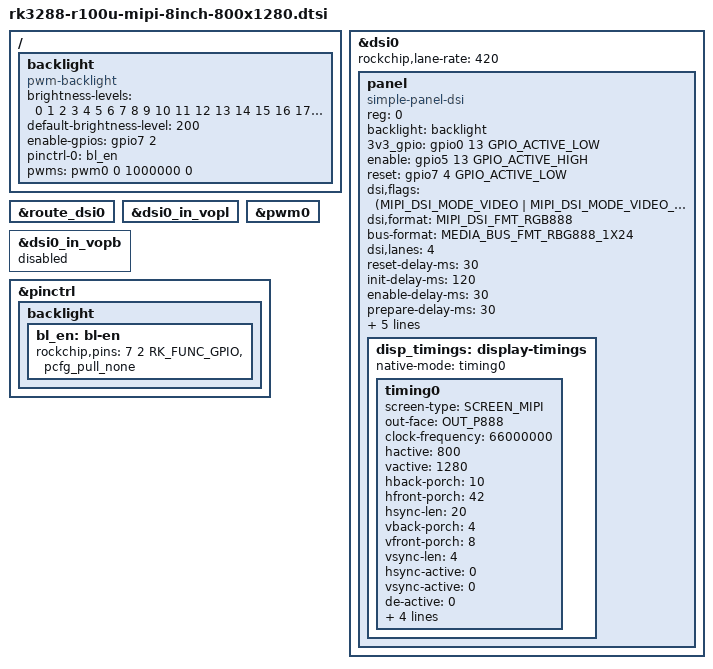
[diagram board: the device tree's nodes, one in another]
// #include <dt-bindings/pwm/pwm.h>
/ {
    /* about backlight */

    backlight: backlight {
    compatible = "pwm-backlight";
    brightness-levels = 
        <
          0   1   2   3   4   5   6   7
          8   9  10  11  12  13  14  15
         16  17  18  19  20  21  22  23
         24  25  26  27  28  29  30  31
         32  33  34  35  36  37  38  39
         40  41  42  43  44  45  46  47
         48  49  50  51  52  53  54  55
         56  57  58  59  60  61  62  63
         64  65  66  67  68  69  70  71
         72  73  74  75  76  77  78  79
         80  81  82  83  84  85  86  87
         88  89  90  91  92  93  94  95
         96  97  98  99 100 101 102 103
        104 105 106 107 108 109 110 111
        112 113 114 115 116 117 118 119
        120 121 122 123 124 125 126 127
        128 129 130 131 132 133 134 135
        136 137 138 139 140 141 142 143
        144 145 146 147 148 149 150 151
        152 153 154 155 156 157 158 159
        160 161 162 163 164 165 166 167
        168 169 170 171 172 173 174 175
        176 177 178 179 180 181 182 183
        184 185 186 187 188 189 190 191
        192 193 194 195 196 197 198 199
        200 201 202 203 204 205 206 207
        208 209 210 211 212 213 214 215
        216 217 218 219 220 221 222 223
        224 225 226 227 228 229 230 231
        232 233 234 235 236 237 238 239
        240 241 242 243 244 245 246 247
        248 249 250 251 252 253 254 255>;
        default-brightness-level = <200>;
        enable-gpios = <&gpio7 2 GPIO_ACTIVE_HIGH>;
        pinctrl-names = "default";
        pinctrl-0 = <&bl_en>;
        pwms = <&pwm0 0 1000000 0>;
    };
};

/************************************** pin description **********************************
 * LCD_RST:             GPIO7_A4, High ---> reset
 * BACKLIGHT_ENABLE:    GPIO7_A2, High ---> enable
 * LCD_PWM              pwm0
 * LCD_STANDY           GPIO7_B2, High ---> enable
 * LCM_3V3_ENABLE       GPIO0_B5, Low  ---> enable
 * LCM_1V8_ENABLE       GPIO5_B5, High  ---> enable
******************************************************************************************/

&dsi0 {
	status = "okay";
	rockchip,lane-rate = <420>;

	panel: panel {
        status = "okay";
		compatible = "simple-panel-dsi";
		reg = <0>;
		backlight = <&backlight>;
        // mipi_standby_gpio = <&gpio7 10 GPIO_ACTIVE_LOW>;
	    3v3_gpio = <&gpio0 13 GPIO_ACTIVE_LOW>;
	    enable = <&gpio5 13 GPIO_ACTIVE_HIGH>;     
        reset = <&gpio7 4 GPIO_ACTIVE_LOW>;
        dsi,flags = <(MIPI_DSI_MODE_VIDEO | MIPI_DSI_MODE_VIDEO_BURST | MIPI_DSI_MODE_LPM)>;
        dsi,format = <MIPI_DSI_FMT_RGB888>;
        bus-format = <MEDIA_BUS_FMT_RBG888_1X24>;
        dsi,lanes = <4>;
        //dsi,channel = <1>;
        reset-delay-ms = <30>;
        init-delay-ms = <120>;
        enable-delay-ms = <30>;
        prepare-delay-ms = <30>;
        unprepare-delay-ms = <30>; 
        panel-init-sequence = [  
            15 00 02 E0 00
            15 00 02 E1 93
            15 00 02 E2 65
            15 00 02 E3 F8
            15 00 02 E0 00
            15 00 02 70 02
            15 00 02 71 23
            15 00 02 72 06
            15 00 02 80 03
            15 00 02 E6 02
            15 00 02 E7 02
            15 00 02 E0 01
            15 00 02 00 00
            15 00 02 01 A0
            15 00 02 03 00
            15 00 02 04 A0
            15 00 02 17 00
            15 00 02 18 B1
            15 00 02 19 00
            15 00 02 1A 00
            15 00 02 1B B1
            15 00 02 1C 00
            15 00 02 1F 3E
            15 00 02 20 2D	
            15 00 02 21 2D
            15 00 02 22 0E
            15 00 02 37 19
            15 00 02 38 05
            15 00 02 39 08
            15 00 02 3A 12
            15 00 02 3C 78
            15 00 02 3E 80
            15 00 02 3F 80
            15 00 02 40 06
            15 00 02 41 A0
            //15 00 02 4A 35  // test mode on
            15 00 02 55 0F
            15 00 02 56 01
            15 00 02 57 69
            15 00 02 58 0A
            15 00 02 59 0A
            15 00 02 5A 28
            15 00 02 5B 19
            15 00 02 5D 7C
            15 00 02 5E 5E
            15 00 02 5F 4E
            15 00 02 60 41
            15 00 02 61 3F
            15 00 02 62 31
            15 00 02 63 37
            15 00 02 64 23
            15 00 02 65 3E
            15 00 02 66 3F
            15 00 02 67 40
            15 00 02 68 5E
            15 00 02 69 4F
            15 00 02 6A 57
            15 00 02 6B 4B
            15 00 02 6C 49
            15 00 02 6D 2F
            15 00 02 6E 03
            15 00 02 6F 00
            15 00 02 70 7C
            15 00 02 71 5E
            15 00 02 72 4E
            15 00 02 73 41
            15 00 02 74 3F
            15 00 02 75 31
            15 00 02 76 37
            15 00 02 77 23
            15 00 02 78 3E 
            15 00 02 79 3F
            15 00 02 7A 40
            15 00 02 7B 5E
            15 00 02 7C 4F
            15 00 02 7D 57
            15 00 02 7E 4B
            15 00 02 7F 49
            15 00 02 80 2F
            15 00 02 81 03
            15 00 02 82 00
            15 00 02 E0 02
            15 00 02 00 47
            15 00 02 01 47  
            15 00 02 02 45
            15 00 02 03 45
            15 00 02 04 4B
            15 00 02 05 4B
            15 00 02 06 49
            15 00 02 07 49
            15 00 02 08 41
            15 00 02 09 1F
            15 00 02 0A 1F
            15 00 02 0B 1F
            15 00 02 0C 1F
            15 00 02 0D 1F
            15 00 02 0E 1F
            15 00 02 0F 43
            15 00 02 10 1F
            15 00 02 11 1F
            15 00 02 12 1F
            15 00 02 13 1F
            15 00 02 14 1F
            15 00 02 15 1F
            15 00 02 16 46
            15 00 02 17 46
            15 00 02 18 44
            15 00 02 19 44
            15 00 02 1A 4A
            15 00 02 1B 4A
            15 00 02 1C 48
            15 00 02 1D 48
            15 00 02 1E 40
            15 00 02 1F 1F
            15 00 02 20 1F
            15 00 02 21 1F
            15 00 02 22 1F
            15 00 02 23 1F
            15 00 02 24 1F
            15 00 02 25 42
            15 00 02 26 1F
            15 00 02 27 1F
            15 00 02 28 1F
            15 00 02 29 1F
            15 00 02 2A 1F
            15 00 02 2B 1F
            15 00 02 58 10 
            15 00 02 59 00 
            15 00 02 5A 00 
            15 00 02 5B 30 
            15 00 02 5C 03 
            15 00 02 5D 30 
            15 00 02 5E 01 
            15 00 02 5F 02 
            15 00 02 60 30 
            15 00 02 61 01 
            15 00 02 62 02 
            15 00 02 63 04 
            15 00 02 64 7F 
            15 00 02 65 05 
            15 00 02 66 12 
            15 00 02 67 73 
            15 00 02 68 05 
            15 00 02 69 04 
            15 00 02 6A 7F 
            15 00 02 6B 09 
            15 00 02 6C 00 
            15 00 02 6D 04 
            15 00 02 6E 04 
            15 00 02 6F 88 
            15 00 02 70 00 
            15 00 02 71 00 
            15 00 02 72 06 
            15 00 02 73 7B 
            15 00 02 74 00 
            15 00 02 75 3C 
            15 00 02 76 00 
            15 00 02 77 0D 
            15 00 02 78 2C 
            15 00 02 79 00 
            15 00 02 7A 00 
            15 00 02 7B 00 
            15 00 02 7C 00 
            15 00 02 7D 03 
            15 00 02 7E 7B 
            15 00 02 E0 01
            15 00 02 0E 01
            15 00 02 E0 03
            15 00 02 98 2F
            15 00 02 E0 04
            15 00 02 2B 2B
            15 00 02 2E 44
            15 00 02 09 10
            15 00 02 2D 03
            15 00 02 E0 00
            05 78 01 11
            05 32 01 29
        ];
                    
        panel-exit-sequence = [
            05 16 01 28
            05 78 01 10
        ];
   
        disp_timings: display-timings {
            native-mode = <&timing0>;
            timing0: timing0 {
                screen-type = <SCREEN_MIPI>;
                out-face    = <OUT_P888>;
                clock-frequency = <66000000>;
                hactive = <800>;
                vactive = <1280>;
                
                hback-porch = <10>;
                hfront-porch = <42>;
                hsync-len = <20>;
                
                vback-porch = <4>;
                vfront-porch = <8>;
                vsync-len = <4>;
                
                
                hsync-active = <0>;
                vsync-active = <0>;
                
                de-active = <0>;
                pixelclk-active = <0>;
                swap-rb = <0>;
                swap-rg = <0>;
                swap-gb = <0>;
            };
        };
    };
};

&route_dsi0 {
	status = "okay";
};

&dsi0_in_vopl {
    status = "okay";
};

&dsi0_in_vopb {
    status = "disabled";
};

&pwm0 {
    status = "okay";
};

&pinctrl {

    backlight {
        bl_en: bl-en {
            rockchip,pins = <7 2 RK_FUNC_GPIO &pcfg_pull_none>;
        };
    };

};
